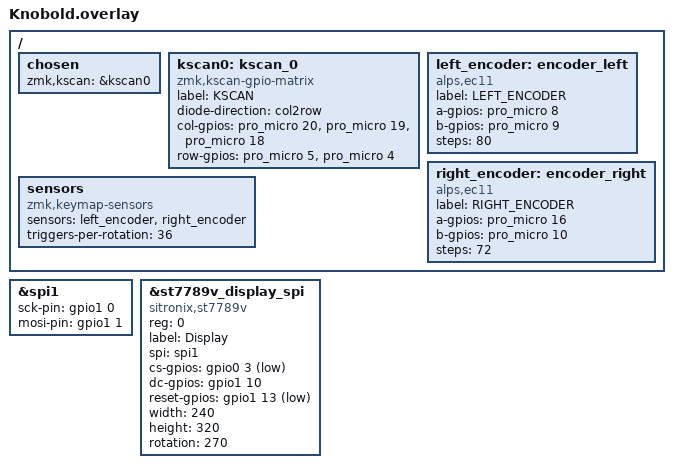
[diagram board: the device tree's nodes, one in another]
/ {
    chosen {
        zmk,kscan = &kscan0;
    };

    kscan0: kscan_0 {
        compatible = "zmk,kscan-gpio-matrix";
        label = "KSCAN";
        diode-direction = "col2row";

        col-gpios
            = <&pro_micro 20 GPIO_ACTIVE_HIGH>
            , <&pro_micro 19 GPIO_ACTIVE_HIGH>
            , <&pro_micro 18 GPIO_ACTIVE_HIGH>
            ;

        row-gpios
            = <&pro_micro 5 (GPIO_ACTIVE_HIGH | GPIO_PULL_DOWN)>
            , <&pro_micro 4 (GPIO_ACTIVE_HIGH | GPIO_PULL_DOWN)>
            ;
        };
left_encoder: encoder_left {
        compatible = "alps,ec11";
        label = "LEFT_ENCODER";
        a-gpios = <&pro_micro 8 (GPIO_ACTIVE_HIGH | GPIO_PULL_UP)>;
        b-gpios = <&pro_micro 9 (GPIO_ACTIVE_HIGH | GPIO_PULL_UP)>;
        steps = <80>;
        };
right_encoder: encoder_right {
        compatible = "alps,ec11";
        label = "RIGHT_ENCODER";
        a-gpios = <&pro_micro 16 (GPIO_ACTIVE_HIGH | GPIO_PULL_UP)>;
        b-gpios = <&pro_micro 10 (GPIO_ACTIVE_HIGH | GPIO_PULL_UP)>;
        steps = <72>;
        };
sensors {
        compatible = "zmk,keymap-sensors";
        sensors = <&left_encoder &right_encoder>;
        triggers-per-rotation = <36>;
        };
};
&spi1 {
    status = "okay";
    sck-pin = <&gpio1 0>;   // SCL: PD0
    mosi-pin = <&gpio1 1>;  // SDA: PD1
};

&st7789v_display_spi {
    compatible = "sitronix,st7789v";
    reg = <0>;
    label = "Display";
    spi = <&spi1>;

    cs-gpios = <&gpio0 3 GPIO_ACTIVE_LOW>;  // CS: PB3
    dc-gpios = <&gpio1 10 GPIO_ACTIVE_HIGH>; // Data/Command pin
    reset-gpios = <&gpio1 13 GPIO_ACTIVE_LOW>; // Reset pin

    width = <240>;
    height = <320>;
    rotation = <270>; // Set rotation; 0, 90, 180, or 270
    status = "okay";
};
